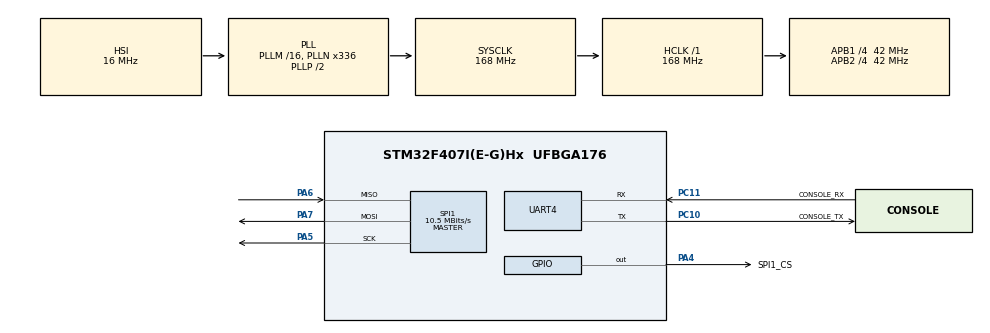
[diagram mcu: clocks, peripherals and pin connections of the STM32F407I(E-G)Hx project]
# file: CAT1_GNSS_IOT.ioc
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FATFS._FS_MINIMIZE=0
Mcu.Family=STM32F4
Mcu.Name=STM32F407I(E-G)Hx
Mcu.Package=UFBGA176
NVIC.PriorityGroup=NVIC_PRIORITYGROUP_4
NVIC.SPI1_IRQn=true\:0\:0\:false\:false\:true\:true
NVIC.UART4_IRQn=true\:0\:0\:true\:false\:true\:true
PA4.GPIO_Label=SPI1_CS
PA4.GPIO_ModeDefaultOutputPP=GPIO_MODE_OUTPUT_PP
PA4.GPIO_PuPd=GPIO_PULLUP
PA4.GPIO_Speed=GPIO_SPEED_FREQ_VERY_HIGH
PA4.PinState=GPIO_PIN_SET
PA4.Signal=GPIO_Output
PA5.GPIO_PuPd=GPIO_PULLUP
PA5.Mode=Full_Duplex_Master
PA5.Signal=SPI1_SCK
PA6.GPIO_PuPd=GPIO_PULLUP
PA6.Mode=Full_Duplex_Master
PA6.Signal=SPI1_MISO
PA7.GPIO_PuPd=GPIO_PULLUP
PA7.Mode=Full_Duplex_Master
PA7.Signal=SPI1_MOSI
PC10.GPIO_Label=CONSOLE_TX
PC10.Mode=Asynchronous
PC10.Signal=UART4_TX
PC11.GPIO_Label=CONSOLE_RX
PC11.Mode=Asynchronous
PC11.Signal=UART4_RX
ProjectManager.HeapSize=0x200
ProjectManager.StackSize=0x400
ProjectManager.TargetToolchain=MDK-ARM V5
RCC.48MHZClocksFreq_Value=84000000
RCC.AHBFreq_Value=168000000
RCC.APB1CLKDivider=RCC_HCLK_DIV4
RCC.APB1Freq_Value=42000000
RCC.APB1TimFreq_Value=84000000
RCC.APB2CLKDivider=RCC_HCLK_DIV4
RCC.APB2Freq_Value=42000000
RCC.APB2TimFreq_Value=84000000
RCC.CortexFreq_Value=168000000
RCC.HCLKFreq_Value=168000000
RCC.HSE_VALUE=25000000
RCC.HSI_VALUE=16000000
RCC.LSE_VALUE=32768
RCC.PLLN=336
RCC.SYSCLKFreq_VALUE=168000000
RCC.SYSCLKSource=RCC_SYSCLKSOURCE_PLLCLK
RCC.VCOOutputFreq_Value=336000000
SPI1.BaudRatePrescaler=SPI_BAUDRATEPRESCALER_4
SPI1.CLKPhase=SPI_PHASE_2EDGE
SPI1.CLKPolarity=SPI_POLARITY_HIGH
SPI1.CRCCalculation=SPI_CRCCALCULATION_DISABLE
SPI1.CalculateBaudRate=10.5 MBits/s
SPI1.Direction=SPI_DIRECTION_2LINES
SPI1.Mode=SPI_MODE_MASTER
SPI1.VirtualType=VM_MASTER
UART4.VirtualMode=Asynchronous
VP_FATFS_VS_Generic.Mode=User_defined
board=CAT1_GNSS_IOT

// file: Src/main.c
/**
  ******************************************************************************
  * File Name          : main.c
  * Description        : Main program body
  ******************************************************************************
  * This notice applies to any and all portions of this file
  * that are not between comment pairs USER CODE BEGIN and
  * USER CODE END. Other portions of this file, whether
  * inserted by the user or by software development tools
  * are owned by their respective copyright owners.
  *
  * Copyright (c) 2017 STMicroelectronics International N.V.
  * All rights reserved.
  *
  * Redistribution and use in source and binary forms, with or without
  * modification, are permitted, provided that the following conditions are met:
  *
  * 1. Redistribution of source code must retain the above copyright notice,
  *    this list of conditions and the following disclaimer.
  * 2. Redistributions in binary form must reproduce the above copyright notice,
  *    this list of conditions and the following disclaimer in the documentation
  *    and/or other materials provided with the distribution.
  * 3. Neither the name of STMicroelectronics nor the names of other
  *    contributors to this software may be used to endorse or promote products
  *    derived from this software without specific written permission.
  * 4. This software, including modifications and/or derivative works of this
  *    software, must execute solely and exclusively on microcontroller or
  *    microprocessor devices manufactured by or for STMicroelectronics.
  * 5. Redistribution and use of this software other than as permitted under
  *    this license is void and will automatically terminate your rights under
  *    this license.
  *
  * THIS SOFTWARE IS PROVIDED BY STMICROELECTRONICS AND CONTRIBUTORS "AS IS"
  * AND ANY EXPRESS, IMPLIED OR STATUTORY WARRANTIES, INCLUDING, BUT NOT
  * LIMITED TO, THE IMPLIED WARRANTIES OF MERCHANTABILITY, FITNESS FOR A
  * PARTICULAR PURPOSE AND NON-INFRINGEMENT OF THIRD PARTY INTELLECTUAL PROPERTY
  * RIGHTS ARE DISCLAIMED TO THE FULLEST EXTENT PERMITTED BY LAW. IN NO EVENT
  * SHALL STMICROELECTRONICS OR CONTRIBUTORS BE LIABLE FOR ANY DIRECT, INDIRECT,
  * INCIDENTAL, SPECIAL, EXEMPLARY, OR CONSEQUENTIAL DAMAGES (INCLUDING, BUT NOT
  * LIMITED TO, PROCUREMENT OF SUBSTITUTE GOODS OR SERVICES; LOSS OF USE, DATA,
  * OR PROFITS; OR BUSINESS INTERRUPTION) HOWEVER CAUSED AND ON ANY THEORY OF
  * LIABILITY, WHETHER IN CONTRACT, STRICT LIABILITY, OR TORT (INCLUDING
  * NEGLIGENCE OR OTHERWISE) ARISING IN ANY WAY OUT OF THE USE OF THIS SOFTWARE,
  * EVEN IF ADVISED OF THE POSSIBILITY OF SUCH DAMAGE.
  *
  ******************************************************************************
  */

#include "main.h"
#include "stm32f4xx_hal.h"
#include "fatfs.h"
#include "spi.h"
#include "usart.h"
#include "gpio.h"

/* USER CODE BEGIN PV */
/* Private variables ---------------------------------------------------------*/

/* USER CODE END PV */

void SystemClock_Config(void);

/* USER CODE BEGIN PFP */
/* Private function prototypes -----------------------------------------------*/

/* USER CODE END PFP */

int main(void)
{

  /* MCU Configuration----------------------------------------------------------*/

  /* Reset of all peripherals, Initializes the Flash interface and the Systick. */
  HAL_Init();

  /* Configure the system clock */
  SystemClock_Config();

  /* Initialize all configured peripherals */
  MX_GPIO_Init();
  MX_UART4_Init();
  MX_SPI1_Init();
  MX_FATFS_Init();

  /* USER CODE BEGIN 2 */
  EN25QXX_Init();

  /* USER CODE END 2 */

  /* Infinite loop */

  //ripple test flash read write.
  /*
  EN25QXX_Write("ripple wang flash test...",0,strlen("ripple wang flash test..."));
  uint8_t  buff[30];
  memset(buff, 0, 30);
  printf("before read buff= %s\r\n", buff);
  EN25QXX_Read(buff,0,25);
  printf("buff= %s\r\n", buff);

  EN25QXX_Erase_Chip();
  memset(buff, 0, 30);
  printf("before read buff= %s\r\n", buff);
  EN25QXX_Read(buff,0,25);
  printf("buff[0]= %x\r\n", buff[0]);
  printf("buff[1]= %x\r\n", buff[1]);
  printf("buff[2]= %x\r\n", buff[2]);
  printf("buff[3]= %x\r\n", buff[3]);
  printf("buff[4]= %x\r\n", buff[4]);
  */

  while (1)
  {

      printf("111111\r\n");

      HAL_Delay(3000);
  }
  /* USER CODE END 3 */

}

/** System Clock Configuration
*/
void SystemClock_Config(void)
{

  RCC_OscInitTypeDef RCC_OscInitStruct;
  RCC_ClkInitTypeDef RCC_ClkInitStruct;

    /**Configure the main internal regulator output voltage
    */
  __HAL_RCC_PWR_CLK_ENABLE();

  __HAL_PWR_VOLTAGESCALING_CONFIG(PWR_REGULATOR_VOLTAGE_SCALE1);

    /**Initializes the CPU, AHB and APB busses clocks
    */
  RCC_OscInitStruct.OscillatorType = RCC_OSCILLATORTYPE_HSI;
  RCC_OscInitStruct.HSIState = RCC_HSI_ON;
  RCC_OscInitStruct.HSICalibrationValue = 16;
  RCC_OscInitStruct.PLL.PLLState = RCC_PLL_ON;
  RCC_OscInitStruct.PLL.PLLSource = RCC_PLLSOURCE_HSI;
  RCC_OscInitStruct.PLL.PLLM = 16;
  RCC_OscInitStruct.PLL.PLLN = 336;
  RCC_OscInitStruct.PLL.PLLP = RCC_PLLP_DIV2;
  RCC_OscInitStruct.PLL.PLLQ = 4;
  if (HAL_RCC_OscConfig(&RCC_OscInitStruct) != HAL_OK)
  {
    _Error_Handler(__FILE__, __LINE__);
  }

    /**Initializes the CPU, AHB and APB busses clocks
    */
  RCC_ClkInitStruct.ClockType = RCC_CLOCKTYPE_HCLK|RCC_CLOCKTYPE_SYSCLK
                              |RCC_CLOCKTYPE_PCLK1|RCC_CLOCKTYPE_PCLK2;
  RCC_ClkInitStruct.SYSCLKSource = RCC_SYSCLKSOURCE_PLLCLK;
  RCC_ClkInitStruct.AHBCLKDivider = RCC_SYSCLK_DIV1;
  RCC_ClkInitStruct.APB1CLKDivider = RCC_HCLK_DIV4;
  RCC_ClkInitStruct.APB2CLKDivider = RCC_HCLK_DIV4;

  if (HAL_RCC_ClockConfig(&RCC_ClkInitStruct, FLASH_LATENCY_5) != HAL_OK)
  {
    _Error_Handler(__FILE__, __LINE__);
  }

    /**Configure the Systick interrupt time
    */
  HAL_SYSTICK_Config(HAL_RCC_GetHCLKFreq()/1000);

    /**Configure the Systick
    */
  HAL_SYSTICK_CLKSourceConfig(SYSTICK_CLKSOURCE_HCLK);

  /* SysTick_IRQn interrupt configuration */
  HAL_NVIC_SetPriority(SysTick_IRQn, 0, 0);
}

void _Error_Handler(char * file, int line)
{
  while(1)
  {
  }
}

/************************ (C) COPYRIGHT STMicroelectronics *****END OF FILE****/
